# wsoc_con_aes_secure register map
Vendor: Texas Instruments
Peripheral module from a debugger description file (folder CC35X1E).
Registers are 32-bit, write-only, reset 0x0 unless marked. A register's access mark holds for its fields unless they carry their own. Offsets are as the file gives them; lines under a group give offsets from that group; [hi:lo] are bit positions; {n}, {i} and the like mark numbered series; 'fields as' and 'values as' point back to an identical list; <NAME> marks a mode.

## wsoc_con_aes_secure
{0x0+4i} aes_key3_{i} (i=0..3)
{0x10+4i} aes_key2_{i} (i=0..3)
{0x20+4i} aes_key_{i} (i=0..7)
{0x40+4i} aes_iv_{i} rw (i=0..3)
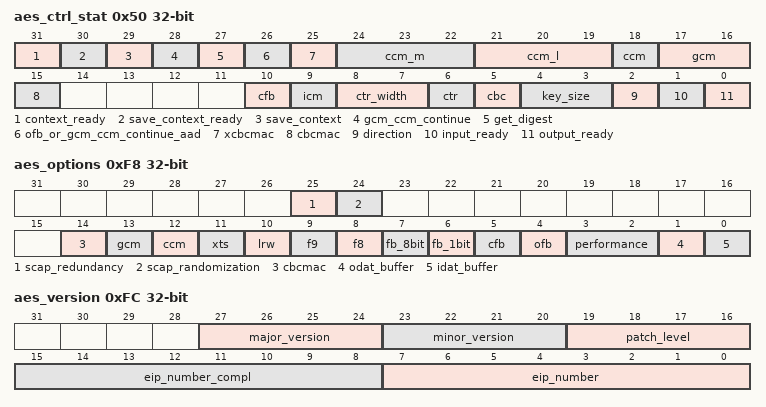
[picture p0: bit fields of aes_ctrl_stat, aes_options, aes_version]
0x50 aes_ctrl_stat access per field reset not defined
  [31] context_ready ro, [30] save_context_ready ro, [29] save_context rw, [28] gcm_ccm_continue wo, [27] get_digest wo, [26] ofb_or_gcm_ccm_continue_aad rw, [25] xcbcmac rw, [24:22] ccm_m rw, [21:19] ccm_l rw, [18] ccm rw, [17:16] gcm rw, [15] cbcmac rw, [10] cfb rw, [9] icm rw, [8:7] ctr_width rw, [6] ctr rw, [5] cbc rw, [4:3] key_size rw, [2] direction rw, [1] input_ready ro, [0] output_ready ro
0x54 aes_length_0
0x58 aes_length_1
0x5C aes_aad_length
{0x60+4i} aes_data_inout_{i} rw (i=0..3)
{0x70+4i} aes_tag_out_{i} ro (i=0..3)
0xD4 aes_ccm_aln_wrd rw
0xD8 aes_blk_cnt_0 rw
  [31:0] aes_blk_cnt
0xDC aes_blk_cnt_1 access per field
  [24:0] aes_blk_cnt rw
0xF4 aes_dma_hs access per field
  [0] dma_data_ack rw
0xF8 aes_options ro reset not defined
  [25] scap_redundancy, [24] scap_randomization, [14] cbcmac, [13] gcm, [12] ccm, [11] xts, [10] lrw, [9] f9, [8] f8, [7] fb_8bit, [6] fb_1bit, [5] cfb, [4] ofb, [3:2] performance, [1] odat_buffer, [0] idat_buffer
0xFC aes_version ro reset not defined
  [27:24] major_version, [23:20] minor_version, [19:16] patch_level, [15:8] eip_number_compl, [7:0] eip_number
